VERSION ""

NS_ :

BS_:

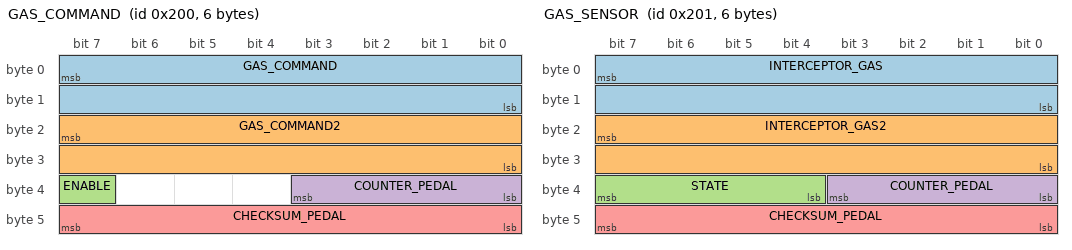
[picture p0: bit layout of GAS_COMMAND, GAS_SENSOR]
BO_ 512 GAS_COMMAND: 6 NEO
 SG_ GAS_COMMAND : 7|16@0+ (0.125677,-75.909) [0|1] "" INTERCEPTOR
 SG_ GAS_COMMAND2 : 23|16@0+ (0.251976,-76.601) [0|1] "" INTERCEPTOR
 SG_ ENABLE : 39|1@0+ (1,0) [0|1] "" INTERCEPTOR
 SG_ COUNTER_PEDAL : 35|4@0+ (1,0) [0|15] "" INTERCEPTOR
 SG_ CHECKSUM_PEDAL : 47|8@0+ (1,0) [0|255] "" INTERCEPTOR

BO_ 513 GAS_SENSOR: 6 INTERCEPTOR
 SG_ INTERCEPTOR_GAS : 7|16@0+ (0.125677,-75.909) [0|1] "" NEO
 SG_ INTERCEPTOR_GAS2 : 23|16@0+ (0.251976,-76.601) [0|1] "" NEO
 SG_ STATE : 39|4@0+ (1,0) [0|15] "" NEO
 SG_ COUNTER_PEDAL : 35|4@0+ (1,0) [0|15] "" NEO
 SG_ CHECKSUM_PEDAL : 47|8@0+ (1,0) [0|255] "" NEO

BO_ 189 EBCMRegenPaddle: 7 K17_EBCM
 SG_ RegenPaddle : 7|4@0+ (1,0) [0|0] ""  NEO

BO_ 190 ECMAcceleratorPos: 6 K20_ECM
 SG_ BrakePedalPos : 15|8@0+ (1,0) [0|0] "sticky"  NEO
 SG_ GasPedalAndAcc : 23|8@0+ (1,0) [0|0] ""  NEO

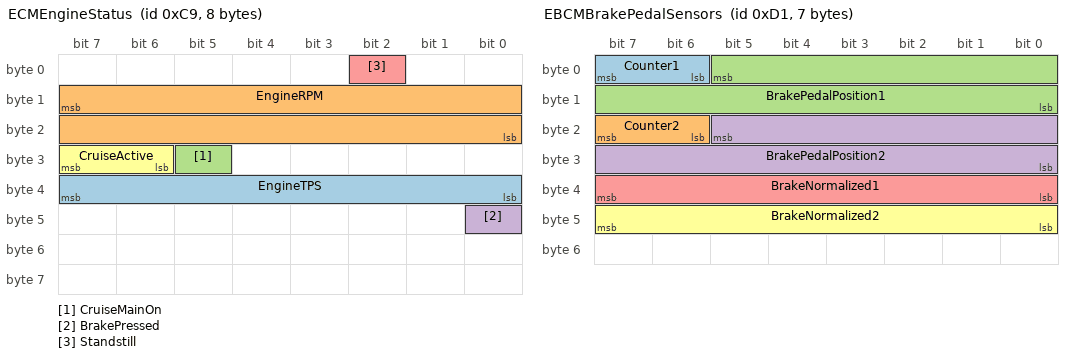
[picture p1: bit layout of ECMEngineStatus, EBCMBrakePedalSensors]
BO_ 201 ECMEngineStatus: 8 K20_ECM
 SG_ EngineTPS : 39|8@0+ (0.392156863,0) [0|100.000000065] "%" NEO
 SG_ EngineRPM : 15|16@0+ (0.25,0) [0|0] "RPM" NEO
 SG_ CruiseMainOn : 29|1@0+ (1,0) [0|1] "" NEO
 SG_ BrakePressed : 40|1@0+ (1,0) [0|1] "" NEO
 SG_ Standstill : 2|1@0+ (1,0) [0|1] "" NEO
 SG_ CruiseActive : 31|2@0+ (1,0) [0|3] "" NEO

BO_ 209 EBCMBrakePedalSensors: 7 K17_EBCM
 SG_ Counter1 : 7|2@0+ (1,0) [0|3] "" XXX
 SG_ Counter2 : 23|2@0+ (1,0) [0|3] "" XXX
 SG_ BrakePedalPosition1 : 5|14@0+ (1,0) [0|16383] "" XXX
 SG_ BrakePedalPosition2 : 21|14@0- (-1,0) [0|16383] "" XXX
 SG_ BrakeNormalized1 : 39|8@0+ (1,0) [0|255] "" XXX
 SG_ BrakeNormalized2 : 47|8@0- (-1,0) [0|255] "" XXX

BO_ 241 EBCMBrakePedalPosition: 6 K17_EBCM
 SG_ BrakePressed : 1|1@0+ (1,0) [0|1] "" XXX
 SG_ BrakePedalPosition : 15|8@0+ (1,0) [0|255] ""  NEO

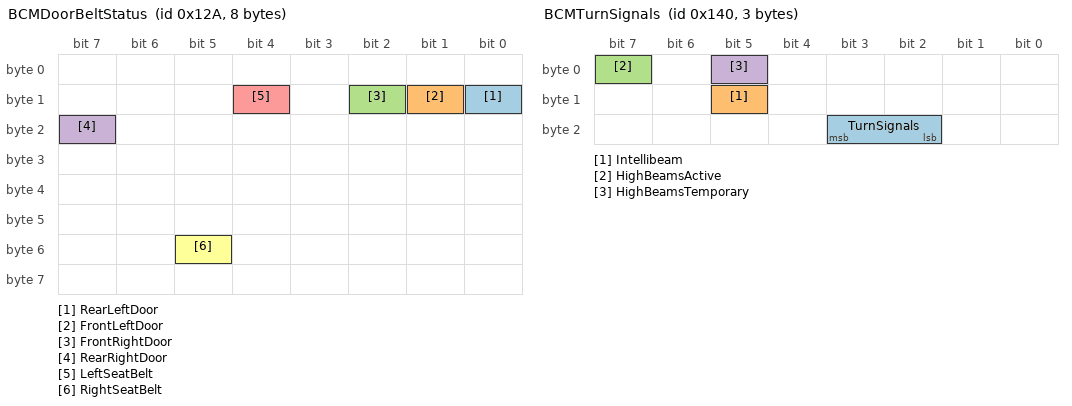
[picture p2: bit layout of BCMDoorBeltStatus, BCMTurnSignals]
BO_ 298 BCMDoorBeltStatus: 8 K9_BCM
 SG_ RearLeftDoor : 8|1@0+ (1,0) [0|0] ""  NEO
 SG_ FrontLeftDoor : 9|1@0+ (1,0) [0|0] ""  NEO
 SG_ FrontRightDoor : 10|1@0+ (1,0) [0|0] ""  NEO
 SG_ RearRightDoor : 23|1@0+ (1,0) [0|0] ""  NEO
 SG_ LeftSeatBelt : 12|1@0+ (1,0) [0|0] ""  NEO
 SG_ RightSeatBelt : 53|1@0+ (1,0) [0|0] ""  NEO

BO_ 309 ECMPRDNL: 8 K20_ECM
 SG_ PRNDL : 2|3@0+ (1,0) [0|0] ""  NEO
 SG_ ESPButton : 4|1@0+ (1,0) [0|1] "" XXX

BO_ 320 BCMTurnSignals: 3 K9_BCM
 SG_ TurnSignals : 19|2@0+ (1,0) [0|0] ""  NEO
 SG_ Intellibeam : 13|1@0+ (1,0) [0|1] "" XXX
 SG_ HighBeamsActive : 7|1@0+ (1,0) [0|1] "" XXX
 SG_ HighBeamsTemporary : 5|1@0+ (1,0) [0|1] "" XXX

BO_ 328 PSCM_148: 1 K43_PSCM

BO_ 381 ESPStatus: 6 K20_ECM
 SG_ TractionControlOn : 5|1@0+ (1,0) [0|0] ""  NEO
 SG_ MSG17D_AccPower : 35|12@0- (1,0) [0|0] ""  NEO

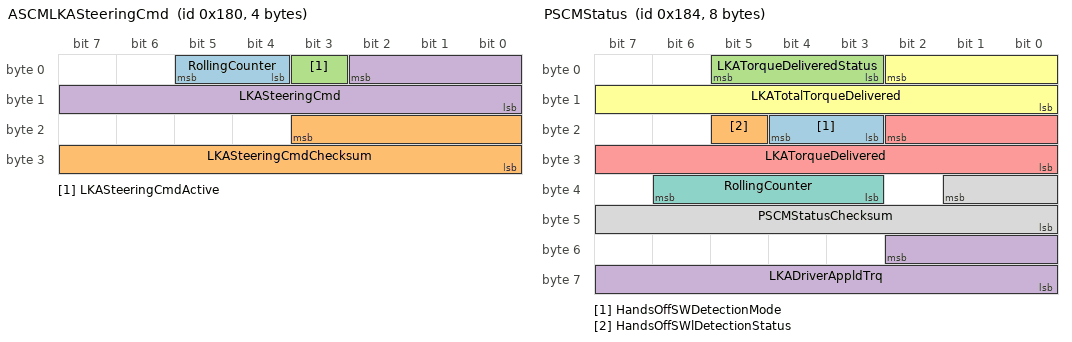
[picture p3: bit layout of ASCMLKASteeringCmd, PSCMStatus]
BO_ 384 ASCMLKASteeringCmd: 4 NEO
 SG_ RollingCounter : 5|2@0+ (1,0) [0|0] ""  NEO
 SG_ LKASteeringCmdChecksum : 19|12@0+ (1,0) [0|0] ""  NEO
 SG_ LKASteeringCmdActive : 3|1@0+ (1,0) [0|0] ""  NEO
 SG_ LKASteeringCmd : 2|11@0- (1,0) [0|0] ""  NEO

BO_ 388 PSCMStatus: 8 K43_PSCM
 SG_ HandsOffSWDetectionMode : 20|2@0+ (1,0) [0|3] "" NEO
 SG_ HandsOffSWlDetectionStatus : 21|1@0+ (1,0) [0|1] "" NEO
 SG_ LKATorqueDeliveredStatus : 5|3@0+ (1,0) [0|7] "" NEO
 SG_ LKADriverAppldTrq : 50|11@0- (0.01,0) [-10.24|10.23] "Nm" NEO
 SG_ LKATorqueDelivered : 18|11@0- (0.01,0) [0|1] "" NEO
 SG_ LKATotalTorqueDelivered : 2|11@0- (0.01,0) [-10.24|10.23] "Nm" NEO
 SG_ RollingCounter : 38|4@0+ (1,0) [0|15] "" XXX
 SG_ PSCMStatusChecksum : 33|10@0+ (1,0) [0|1023] "" XXX

BO_ 417 AcceleratorPedal: 7 XXX
 SG_ AcceleratorPedal : 55|8@0+ (1,0) [0|0] ""  NEO

BO_ 451 GasAndAcc: 8 XXX
 SG_ GasPedalAndAcc2 : 55|8@0+ (1,0) [0|0] ""  NEO

BO_ 452 AcceleratorPedal2: 8 XXX
 SG_ CruiseState : 15|3@0+ (1,0) [0|7] ""  NEO
 SG_ AcceleratorPedal2 : 47|8@0+ (1,0) [0|0] ""  NEO

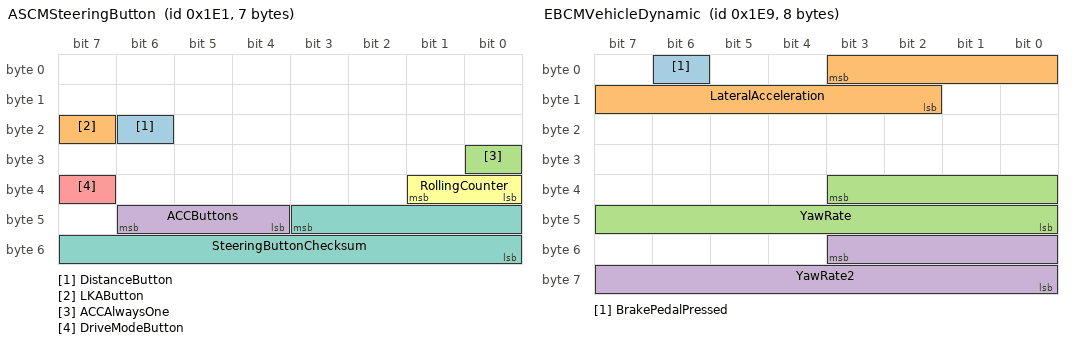
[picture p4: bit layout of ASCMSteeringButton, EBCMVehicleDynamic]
BO_ 481 ASCMSteeringButton: 7 K124_ASCM
 SG_ DistanceButton : 22|1@0+ (1,0) [0|0] ""  NEO
 SG_ LKAButton : 23|1@0+ (1,0) [0|0] ""  NEO
 SG_ ACCAlwaysOne : 24|1@0+ (1,0) [0|1] "" XXX
 SG_ ACCButtons : 46|3@0+ (1,0) [0|0] ""  NEO
 SG_ DriveModeButton : 39|1@0+ (1,0) [0|1] "" XXX
 SG_ RollingCounter : 33|2@0+ (1,0) [0|3] "" NEO
 SG_ SteeringButtonChecksum : 43|12@0+ (1,0) [0|255] "" NEO

BO_ 485 PSCMSteeringAngle: 8 K43_PSCM
 SG_ SteeringWheelAngle : 15|16@0- (0.0625,0) [-2047|2047] "deg"  NEO
 SG_ SteeringWheelRate : 27|12@0- (1,0) [-2047|2047] "deg/s"  NEO

BO_ 489 EBCMVehicleDynamic: 8 K17_EBCM
 SG_ BrakePedalPressed : 6|1@0+ (1,0) [0|0] "" NEO
 SG_ LateralAcceleration : 3|10@0- (0.161,0) [-2047|2047] "m/s2" NEO
 SG_ YawRate : 35|12@0- (0.625,0) [0|1] "" NEO
 SG_ YawRate2 : 51|12@0- (0.0625,0) [-2047|2047] "grad/s" NEO

BO_ 352 BCMImmobilizer: 5 K9_BCM
 SG_ ImmobilizerInfo : 7|32@0+ (1,0) [0|4294967295] "" XXX

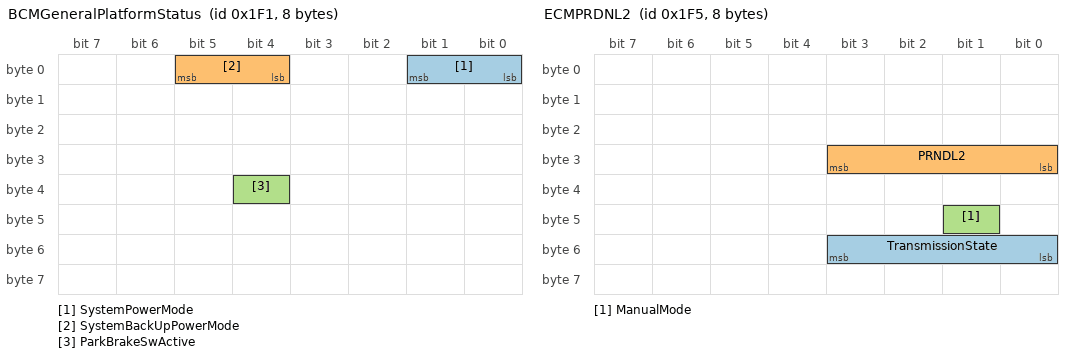
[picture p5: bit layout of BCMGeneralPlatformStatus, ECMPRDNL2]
BO_ 497 BCMGeneralPlatformStatus: 8 K9_BCM
 SG_ SystemPowerMode : 1|2@0+ (1,0) [0|3] "" XXX
 SG_ SystemBackUpPowerMode : 5|2@0+ (1,0) [0|3] "" XXX
 SG_ ParkBrakeSwActive : 36|1@0+ (1,0) [0|3] "" XXX

BO_ 501 ECMPRDNL2: 8 K20_ECM
 SG_ TransmissionState : 48|4@1+ (1,0) [0|7] "" NEO
 SG_ PRNDL2 : 27|4@0+ (1,0) [0|255] "" NEO
 SG_ ManualMode : 41|1@0+ (1,0) [0|1] "" NEO

BO_ 532 BRAKE_RELATED: 6 XXX
 SG_ UserBrakePressure : 0|9@0+ (1,0) [0|511] "" XXX

BO_ 560 EPBStatus: 8 EPB
 SG_ EPBClosed : 12|1@0+ (1,0) [0|1] ""  NEO

BO_ 562 EBCMFrictionBrakeStatus: 8 K17_EBCM
 SG_ FrictionBrakeUnavailable : 46|1@0+ (1,0) [0|1] "" XXX

BO_ 608 SPEED_RELATED: 8 XXX
 SG_ RollingCounter : 5|2@0+ (1,0) [0|0] "" XXX
 SG_ ClusterSpeed : 31|8@0+ (1,0) [0|0] "" XXX

BO_ 711 BECMBatteryVoltageCurrent: 6 K17_EBCM
 SG_ HVBatteryVoltage : 31|12@0+ (0.125,0) [0|511.875] "V"  NEO
 SG_ HVBatteryCurrent : 12|13@0- (0.15,0) [-614.4|614.25] "A"  NEO

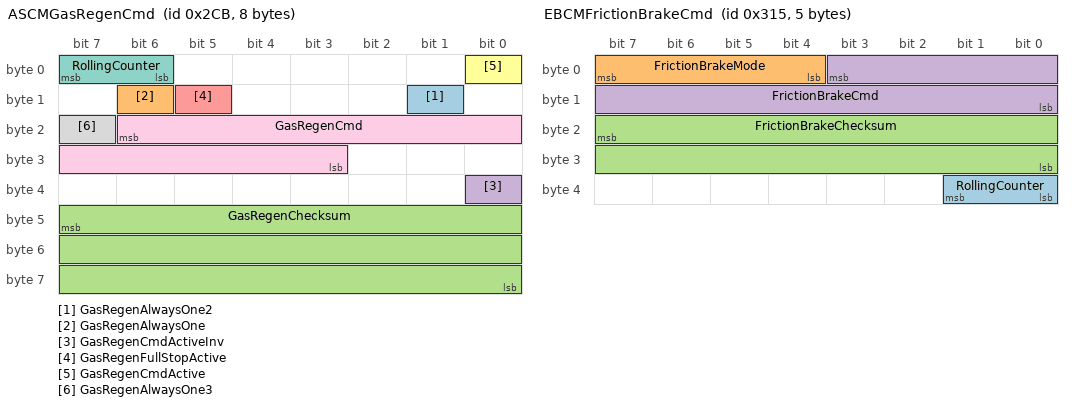
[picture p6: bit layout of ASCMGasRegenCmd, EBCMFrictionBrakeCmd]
BO_ 715 ASCMGasRegenCmd: 8 K124_ASCM
 SG_ GasRegenAlwaysOne2 : 9|1@0+ (1,0) [0|1] ""  NEO
 SG_ GasRegenAlwaysOne : 14|1@0+ (1,0) [0|1] ""  NEO
 SG_ GasRegenChecksum : 47|24@0+ (1,0) [0|0] ""  NEO
 SG_ GasRegenCmdActiveInv : 32|1@0+ (1,0) [0|0] ""  NEO
 SG_ GasRegenFullStopActive : 13|1@0+ (1,0) [0|0] ""  NEO
 SG_ GasRegenCmdActive : 0|1@0+ (1,0) [0|0] ""  NEO
 SG_ RollingCounter : 7|2@0+ (1,0) [0|0] ""  NEO
 SG_ GasRegenAlwaysOne3 : 23|1@0+ (1,0) [0|1] ""  NEO
 SG_ GasRegenCmd : 22|12@0+ (1,0) [0|0] ""  NEO

BO_ 717 ASCM_2CD: 5 K124_ASCM

BO_ 761 BRAKE_RELATED_2: 7 XXX
 SG_ UserBrakePressure2 : 47|9@0+ (1,0) [0|511] "" XXX

BO_ 789 EBCMFrictionBrakeCmd: 5 K124_ASCM
 SG_ RollingCounter : 33|2@0+ (1,0) [0|0] ""  NEO
 SG_ FrictionBrakeMode : 7|4@0+ (1,0) [0|0] ""  NEO
 SG_ FrictionBrakeChecksum : 23|16@0+ (1,0) [0|0] ""  NEO
 SG_ FrictionBrakeCmd : 3|12@0- (1,0) [0|0] ""  NEO

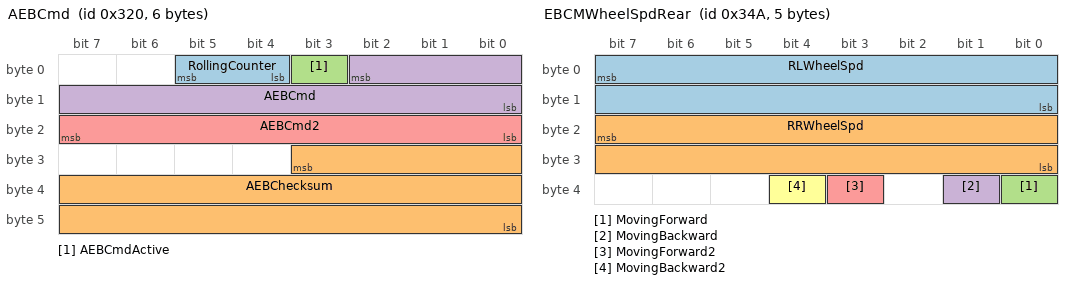
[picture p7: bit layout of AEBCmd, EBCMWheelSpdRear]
BO_ 800 AEBCmd: 6 K124_ASCM
 SG_ RollingCounter : 5|2@0+ (1,0) [0|3] "" NEO
 SG_ AEBChecksum : 27|20@0+ (1,0) [0|0] "" NEO
 SG_ AEBCmdActive : 3|1@1+ (1,0) [0|1] "" NEO
 SG_ AEBCmd : 2|11@0+ (1,0) [0|0] "" NEO
 SG_ AEBCmd2 : 23|8@0+ (1,0) [0|0] "" NEO

BO_ 810 TCICOnStarGPSPosition: 8 K73_TCIC
 SG_ GPSLongitude : 39|32@0+ (1,-2147483648) [0|0] "milliarcsecond"  NEO
 SG_ GPSLatitude : 7|32@0+ (1,0) [0|0] "milliarcsecond"  NEO

BO_ 840 EBCMWheelSpdFront: 5 K17_EBCM
 SG_ FLWheelSpd : 7|16@0+ (0.0311,0) [0|255] "km/h"  NEO
 SG_ FRWheelSpd : 23|16@0+ (0.0311,0) [0|255] "km/h"  NEO

BO_ 842 EBCMWheelSpdRear: 5 K17_EBCM
 SG_ RLWheelSpd : 7|16@0+ (0.0311,0) [0|255] "km/h"  NEO
 SG_ RRWheelSpd : 23|16@0+ (0.0311,0) [0|255] "km/h"  NEO
 SG_ MovingForward : 32|1@0+ (1,0) [0|1] "" XXX
 SG_ MovingBackward : 33|1@0+ (1,0) [0|1] "" XXX
 SG_ MovingForward2 : 35|1@1+ (1,0) [0|1] "" XXX
 SG_ MovingBackward2 : 36|1@0+ (1,0) [0|1] "" XXX

BO_ 869 ASCM_365: 4 K124_ASCM

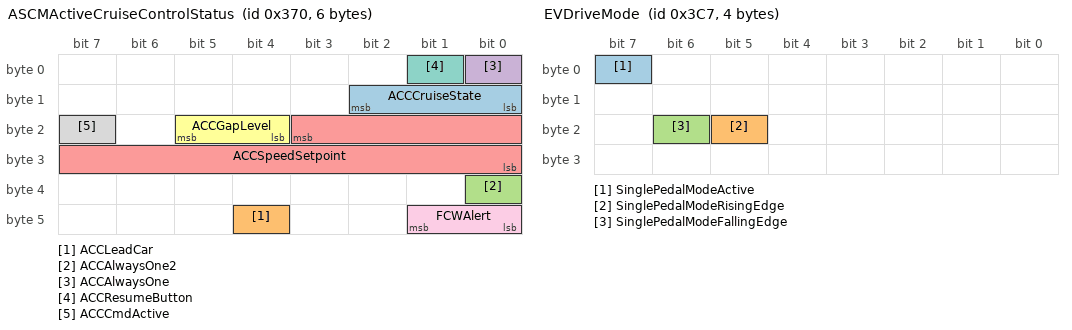
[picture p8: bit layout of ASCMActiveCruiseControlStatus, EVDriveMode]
BO_ 880 ASCMActiveCruiseControlStatus: 6 K124_ASCM
 SG_ ACCCruiseState : 8|3@1+ (1,0) [0|7] "" XXX
 SG_ ACCLeadCar : 44|1@0+ (1,0) [0|0] "" Vector__XXX
 SG_ ACCAlwaysOne2 : 32|1@0+ (1,0) [0|0] "" Vector__XXX
 SG_ ACCAlwaysOne : 0|1@0+ (1,0) [0|0] "" Vector__XXX
 SG_ ACCSpeedSetpoint : 19|12@0+ (0.0625,0) [0|255.9375] "km/h"  NEO
 SG_ ACCGapLevel : 21|2@0+ (1,0) [0|0] ""  NEO
 SG_ ACCResumeButton : 1|1@0+ (1,0) [0|0] ""  NEO
 SG_ ACCCmdActive : 23|1@0+ (1,0) [0|0] ""  NEO
 SG_ FCWAlert : 41|2@0+ (1,0) [0|3] "" XXX

BO_ 967 EVDriveMode: 4 XXX
 SG_ SinglePedalModeActive : 7|1@0+ (1,0) [0|1] "" XXX
 SG_ SinglePedalModeRisingEdge : 21|1@0+ (1,0) [0|1] "" XXX
 SG_ SinglePedalModeFallingEdge : 22|1@0+ (1,0) [0|1] "" XXX

BO_ 977 ECMCruiseControl: 8 K20_ECM
 SG_ CruiseActive : 39|1@0+ (1,0) [0|3] "" NEO
 SG_ CruiseSetSpeed : 19|12@0+ (0.0625,0) [0|0] "km/h" NEO

BO_ 1001 ECMVehicleSpeed: 8 K20_ECM
 SG_ VehicleSpeed : 7|16@0+ (0.01,0) [0|0] "mph"  NEO
 SG_ VehicleSpeedLeft : 39|16@0+ (0.01,0) [0|0] "mph" NEO

BO_ 1033 ASCMKeepAlive: 7 NEO
 SG_ ASCMKeepAliveAllZero : 7|56@0+ (1,0) [0|0] ""  NEO

BO_ 1034 ASCM_40A: 7 K124_ASCM

BO_ 1217 ECMEngineCoolantTemp: 8 K20_ECM
 SG_ EngineCoolantTemp : 23|8@0+ (1,-40) [0|0] "C"  NEO

BO_ 1249 VIN_Part2: 8 K20_ECM
 SG_ VINPart2 : 7|64@0+ (1,0) [0|0] ""  NEO

BO_ 1296 ASCM_510: 4 K124_ASCM

BO_ 1300 VIN_Part1: 8 K20_ECM
 SG_ VINPart1 : 7|64@0+ (1,0) [0|0] ""  NEO

BO_ 1912 PSCM_778: 8 K43_PSCM

BO_ 1930 ASCM_78A: 7 K124_ASCM

BO_TX_BU_ 384 : K124_ASCM,NEO;
BO_TX_BU_ 880 : NEO,K124_ASCM;
BO_TX_BU_ 1033 : K124_ASCM,NEO;
BO_TX_BU_ 715 : NEO,K124_ASCM;
BO_TX_BU_ 789 : NEO,K124_ASCM;
BO_TX_BU_ 800 : NEO,K124_ASCM;

BU_: AWD ECU TCU ESP SAS ABS

CM_ SG_ 357 GEAR "13P, 26R, 13N, 24D";
CM_ SG_ 605 PED_BRAKE "3: no brake, 4: brake";
CM_ SG_ 605 BRAKE_WARNING "Flashing brake warning and audible alert for potential forward collision";
CM_ SG_ 579 STEERING_ANGLE "steering angle aligns with 0.022 factor and -45.06 offset";
CM_ SG_ 863 SPEED_SIGN "speed limit in MPH";
CM_ SG_ 863 SPEED_SIGN_CAM "1: The speed limit is recognized by the camera. 0: speed limit is map based or is not available";
CM_ SG_ 863 STOP_SIGN "value 9 when stop sign is active";
CM_ SG_ 1157 SBS_WARNING_DISTANCE "1 far, 2 mid, 3 near";
CM_ SG_ 1157 SBS_SCBC "1 off, 2 on";
CM_ SG_ 1157 LKAS_ASSIT_TIMING "1 at, 0 before";
CM_ SG_ 1157 LKAS_SENSETIVITY "0 low, 1 high";
CM_ SG_ 1157 LANEE_DEPARTURE_ALERT "1 off, 2 on";
CM_ SG_ 1157 WARNING "1 Rare, 0 often";
CM_ SG_ 1088 LANE_LINES "0 LKAS disabled, 1 no lines, 2 two lines, 3 left line, 4 right line";
CM_ SG_ 1088 TJA "2: crz not active,  3: TJA not allowed,  4: TJA allowed";
CM_ SG_ 1088 TJA_TRANSITION "3: if TJA signal is 3, otherwise set to 0";
CM_ SG_ 1045 ABS_MALFUNCTION "off: 0, solid: 1, slow blink: 2, fast blink: 3";
CM_ SG_ 120 VEHICLE_ACC_X "Vehicle acceleration of X-axis wrt. NED frame.";
CM_ SG_ 120 VEHICLE_ACC_Y "Vehicle acceleration of Y-axis wrt. NED frame.";
CM_ SG_ 157 CAN_OFF "Disengage Cruise if enabled, if already disabled  TURN it OFF ";
CM_ SG_ 552 GEAR "0 Shifting, 1 P, 2 R, 3 N, 4 D";
CM_ SG_ 552 GEAR_BOX "0 P, 14 R, 1 though 6 D for speeds, 15 Shift";
CM_ SG_ 540 HANDS_ON_STEER_WARN "0 no warning, b warning";
CM_ SG_ 540 DISTANCE_SETTING "Radar distance 0: disabled, 1: 4 bars, 2: 3 bars, 3: 2 bars, 4: 1 bar";
CM_ SG_ 1143 REAR_CT_ALERT "Rear Cross Traffic Alert";
VAL_ 3 StW_Angl 16383 "SNA" ;
VAL_ 3 StW_AnglSens_Id 2 "MUST" 0 "PSBL" 1 "SELF" ;
VAL_ 3 StW_AnglSens_Stat 2 "ERR" 3 "ERR_INI" 1 "INI" 0 "OK" ;
VAL_ 3 StW_AnglSpd 16383 "SNA" ;
VAL_ 14 StW_AnglHP 16383 "SNA" ;
VAL_ 14 StW_AnglHP_Spd 16383 "SNA" ;
VAL_ 14 StW_AnglHP_Sens_Stat 3 "SNA" 2 "ERR" 1 "INI" 0 "OK" ;
VAL_ 14 StW_AnglHP_Sens_Id 3 "SNA" 2 "KOSTAL" 1 "DELPHI" 0 "TEST" ;
VAL_ 69 SpdCtrlLvr_Stat 32 "DN_1ST" 16 "UP_1ST" 8 "DN_2ND" 4 "UP_2ND" 2 "RWD" 1 "FWD" 0 "IDLE" ;
VAL_ 69 DTR_Dist_Rq 255 "SNA" 200 "ACC_DIST_7" 166 "ACC_DIST_6" 133 "ACC_DIST_5" 100 "ACC_DIST_4" 66 "ACC_DIST_3" 33 "ACC_DIST_2" 0 "ACC_DIST_1" ;
VAL_ 69 TurnIndLvr_Stat 3 "SNA" 2 "RIGHT" 1 "LEFT" 0 "IDLE" ;
VAL_ 69 HiBmLvr_Stat 3 "SNA" 2 "HIBM_FLSH_ON_PSD" 1 "HIBM_ON_PSD" 0 "IDLE" ;
VAL_ 69 WprWashSw_Psd 3 "SNA" 2 "WASH" 1 "TIPWIPE" 0 "NPSD" ;
VAL_ 69 WprWash_R_Sw_Posn_V2 3 "SNA" 2 "WASH" 1 "INTERVAL" 0 "OFF" ;
VAL_ 69 StW_Lvr_Stat 4 "STW_BACK" 3 "STW_FWD" 2 "STW_DOWN" 1 "STW_UP" 0 "NPSD" ;
VAL_ 69 StW_Cond_Psd 3 "SNA" 2 "DOWN" 1 "UP" 0 "NPSD" ;
VAL_ 69 HrnSw_Psd 3 "SNA" 2 "NDEF2" 1 "PSD" 0 "NPSD" ;
VAL_ 69 StW_Sw00_Psd 1 "PRESSED" 0 "NOT_PRESSED_SNA" ;
VAL_ 69 StW_Sw01_Psd 1 "PRESSED" 0 "NOT_PRESSED_SNA" ;
VAL_ 69 StW_Sw03_Psd 1 "PRESSED" 0 "NOT_PRESSED_SNA" ;
VAL_ 69 StW_Sw04_Psd 1 "PRESSED" 0 "NOT_PRESSED_SNA" ;
VAL_ 69 WprSw6Posn 7 "SNA" 6 "STAGE2" 5 "STAGE1" 4 "INTERVAL4" 3 "INTERVAL3" 2 "INTERVAL2" 1 "INTERVAL1" 0 "OFF" ;
VAL_ 257 GTW_epasControlType 0 "WITHOUT" 1 "WITH_ANGLE" 3 "WITH_BOTH" 2 "WITH_TORQUE" ;
VAL_ 109 StW_Sw_Stat3 7 "SNA" 6 "NDEF6" 5 "NDEF5" 4 "NDEF4" 3 "PLUS_MINUS" 2 "MINUS" 1 "PLUS" 0 "NPSD" ;
VAL_ 109 MsgTxmtId 3 "NDEF3" 2 "NDEF2" 1 "SCCM" 0 "EWM" ;
VAL_ 109 TSL_RND_Posn_StW 15 "SNA" 8 "D" 6 "INI" 4 "N_DOWN" 2 "N_UP" 1 "R" 0 "IDLE" ;
VAL_ 109 TSL_P_Psd_StW 3 "SNA" 2 "INI" 1 "PSD" 0 "IDLE" ;
VAL_ 257 GTW_epasEmergencyOn 1 "EMERGENCY_POWER" 0 "NONE" ;
VAL_ 257 GTW_epasLDWEnabled 1 "ALLOWED" 0 "INHIBITED" ;
VAL_ 257 GTW_epasPowerMode 0 "DRIVE_OFF" 1 "DRIVE_ON" 3 "LOAD_SHED" 2 "SHUTTING_DOWN" 15 "SNA" ;
VAL_ 257 GTW_epasTuneRequest 1 "DM_COMFORT" 3 "DM_SPORT" 2 "DM_STANDARD" 0 "FAIL_SAFE_DEFAULT" 4 "RWD_COMFORT" 6 "RWD_SPORT" 5 "RWD_STANDARD" 7 "SNA" ;
VAL_ 264 DI_torqueDriver -4096 "SNA" ;
VAL_ 264 DI_torqueMotor -4096 "SNA" ;
VAL_ 264 DI_soptState 7 "SOPT_TEST_SNA" 4 "SOPT_TEST_NOT_RUN" 3 "SOPT_TEST_PASSED" 2 "SOPT_TEST_FAILED" 1 "SOPT_TEST_IN_PROGRESS" 0 "SOPT_PRE_TEST" ;
VAL_ 264 DI_motorRPM -32768 "SNA" ;
VAL_ 264 DI_pedalPos 255 "SNA" ;
VAL_ 280 DI_torqueEstimate -2048 "SNA" ;
VAL_ 280 DI_gear 7 "DI_GEAR_SNA" 4 "DI_GEAR_D" 3 "DI_GEAR_N" 2 "DI_GEAR_R" 1 "DI_GEAR_P" 0 "DI_GEAR_INVALID" ;
VAL_ 280 DI_brakePedal 1 "Applied" 0 "Not_applied" ;
VAL_ 280 DI_vehicleSpeed 4095 "SNA" ;
VAL_ 280 DI_gearRequest 7 "DI_GEAR_SNA" 4 "DI_GEAR_D" 3 "DI_GEAR_N" 2 "DI_GEAR_R" 1 "DI_GEAR_P" 0 "DI_GEAR_INVALID" ;
VAL_ 280 DI_torqueInterfaceFailure 1 "TORQUE_INTERFACE_FAILED" 0 "TORQUE_INTERFACE_NORMAL" ;
VAL_ 280 DI_brakePedalState 3 "SNA" 2 "INVALID" 1 "ON" 0 "OFF" ;
VAL_ 280 DI_epbParkRequest 1 "Park_requested" 0 "No_request" ;
VAL_ 280 DI_epbInterfaceReady 1 "EPB_INTERFACE_READY" 0 "EPB_INTERFACE_NOT_READY" ;
VAL_ 309 ESP_absBrakeEvent 1 "ACTIVE" 0 "NOT_ACTIVE" ;
VAL_ 309 ESP_brakeDiscWipingActive 1 "ACTIVE" 0 "INACTIVE" ;
VAL_ 309 ESP_brakeLamp 0 "OFF" 1 "ON" ;
VAL_ 309 ESP_espFaultLamp 0 "OFF" 1 "ON" ;
VAL_ 309 ESP_espLampFlash 1 "FLASH" 0 "OFF" ;
VAL_ 309 ESP_hillStartAssistActive 1 "ACTIVE" 0 "INACTIVE" 2 "NOT_AVAILABLE" 3 "SNA" ;
VAL_ 309 ESP_absFaultLamp 0 "OFF" 1 "ON" ;
VAL_ 309 ESP_espOffLamp 0 "OFF" 1 "ON" ;
VAL_ 309 ESP_stabilityControlSts 2 "ENGAGED" 3 "FAULTED" 5 "INIT" 4 "NOT_CONFIGURED" 0 "OFF" 1 "ON" ;
VAL_ 309 ESP_tcLampFlash 1 "FLASH" 0 "OFF" ;
VAL_ 568 UI_mapSpeedLimit 31 "SNA" 30 "UNLIMITED" 29 "LESS_OR_EQ_160" 28 "LESS_OR_EQ_150" 27 "LESS_OR_EQ_140" 26 "LESS_OR_EQ_130" 25 "LESS_OR_EQ_120" 24 "LESS_OR_EQ_115" 23 "LESS_OR_EQ_110" 22 "LESS_OR_EQ_105" 21 "LESS_OR_EQ_100" 20 "LESS_OR_EQ_95" 19 "LESS_OR_EQ_90" 18 "LESS_OR_EQ_85" 17 "LESS_OR_EQ_80" 16 "LESS_OR_EQ_75" 15 "LESS_OR_EQ_70" 14 "LESS_OR_EQ_65" 13 "LESS_OR_EQ_60" 12 "LESS_OR_EQ_55" 11 "LESS_OR_EQ_50" 10 "LESS_OR_EQ_45" 9 "LESS_OR_EQ_40" 8 "LESS_OR_EQ_35" 7 "LESS_OR_EQ_30" 6 "LESS_OR_EQ_25" 5 "LESS_OR_EQ_20" 4 "LESS_OR_EQ_15" 3 "LESS_OR_EQ_10" 2 "LESS_OR_EQ_7" 1 "LESS_OR_EQ_5" 0 "UNKNOWN" ;
VAL_ 569 DAS_leftLineUsage 3 "BLACKLISTED" 2 "FUSED" 1 "AVAILABLE" 0 "REJECTED_UNAVAILABLE" ;
VAL_ 569 DAS_rightLineUsage 3 "BLACKLISTED" 2 "FUSED" 1 "AVAILABLE" 0 "REJECTED_UNAVAILABLE" ;
VAL_ 569 DAS_leftFork 3 "LEFT_FORK_UNAVAILABLE" 2 "LEFT_FORK_SELECTED" 1 "LEFT_FORK_AVAILABLE" 0 "LEFT_FORK_NONE" ;
VAL_ 569 DAS_rightFork 3 "RIGHT_FORK_UNAVAILABLE" 2 "RIGHT_FORK_SELECTED" 1 "RIGHT_FORK_AVAILABLE" 0 "RIGHT_FORK_NONE" ;
VAL_ 521 DAS_locMode 3 "DAS_LOC_DRIVERLESS" 2 "DAS_LOC_RESTRICTED" 1 "DAS_LOC_NORMAL" 0 "DAS_LOC_OFF" ;
VAL_ 521 DAS_locState 7 "DAS_LOC_FAULT_SNA" 6 "DAS_LOC_AEB_ACTIVE" 2 "DAS_LOC_CANCEL_SILENT" 1 "DAS_LOC_CANCEL_GENERIC" 0 "DAS_LOC_HEALTHY" ;
VAL_ 521 DAS_locRequest 4 "DAS_RQ_PARK" 3 "DAS_RQ_HOLD" 2 "DAS_RQ_BACKWARD" 1 "DAS_RQ_FORWARD" 0 "DAS_RQ_IDLE" ;
VAL_ 521 DAS_locJerkMin 255 "SNA" ;
VAL_ 521 DAS_locJerkMax 255 "SNA" ;
VAL_ 521 DAS_locSpeed 2047 "SNA" ;
VAL_ 521 DAS_locAccelMin 511 "SNA" ;
VAL_ 521 DAS_locAccelMax 511 "SNA" ;
VAL_ 522 driverBrakeStatus 2 "APPLIED" 1 "NOT_APPLIED" ;
VAL_ 760 UI_mapSpeedLimitUnits 1 "KPH" 0 "MPH" ;
VAL_ 760 UI_userSpeedOffsetUnits 1 "KPH" 0 "MPH" ;
VAL_ 643 AirTemp_Insd 255 "SNA" ;
VAL_ 643 AirTemp_Outsd 254 "INIT" 255 "SNA" ;
VAL_ 643 Bckl_Sw_RL_Stat_SAM_R 2 "FLT" 1 "NOT" 0 "OK" 3 "SNA" ;
VAL_ 643 Bckl_Sw_RM_Stat_SAM_R 2 "FLT" 1 "NOT" 0 "OK" 3 "SNA" ;
VAL_ 643 Bckl_Sw_RR_Stat_SAM_R 2 "FLT" 1 "NOT" 0 "OK" 3 "SNA" ;
VAL_ 643 DL_RLtch_Stat 1 "CLS" 0 "NDEF0" 2 "OPN" 3 "SNA" ;
VAL_ 643 DrRLtch_FL_Stat 1 "CLS" 0 "NDEF0" 2 "OPN" 3 "SNA" ;
VAL_ 643 DrRLtch_FR_Stat 1 "CLS" 0 "NDEF0" 2 "OPN" 3 "SNA" ;
VAL_ 643 DrRLtch_RL_Stat 1 "CLS" 0 "NDEF0" 2 "OPN" 3 "SNA" ;
VAL_ 643 DrRLtch_RR_Stat 1 "CLS" 0 "NDEF0" 2 "OPN" 3 "SNA" ;
VAL_ 643 EngHd_Stat 1 "CLS" 0 "NDEF0" 2 "OPN" 3 "SNA" ;
VAL_ 643 LgtSens_Night 0 "DAY" 1 "NIGHT" ;
VAL_ 643 MPkBrk_Stat 1 "ENGG" 0 "RELS" ;
VAL_ 643 RevGr_Engg 0 "DISENGG" 1 "ENGG" 2 "NDEF2" 3 "SNA" ;
VAL_ 643 StW_Cond_Stat 3 "BLINK" 1 "NDEF1" 0 "OFF" 2 "ON" ;
VAL_ 643 Trlr_Stat 2 "NDEF2" 0 "NONE" 1 "OK" 3 "SNA" ;
VAL_ 697 DAS_setSpeed 4095 "SNA" ;
VAL_ 697 DAS_accState 15 "FAULT_SNA" 13 "ACC_CANCEL_GENERIC_SILENT" 11 "APC_SELFPARK_START" 10 "APC_UNPARK_COMPLETE" 9 "APC_PAUSE" 8 "APC_ABORT" 7 "APC_COMPLETE" 6 "APC_FORWARD" 5 "APC_BACKWARD" 4 "ACC_ON" 3 "ACC_HOLD" 0 "ACC_CANCEL_GENERIC" ;
VAL_ 697 DAS_aebEvent 3 "AEB_SNA" 2 "AEB_FAULT" 1 "AEB_ACTIVE" 0 "AEB_NOT_ACTIVE" ;
VAL_ 697 DAS_jerkMin 511 "SNA" ;
VAL_ 697 DAS_jerkMax 255 "SNA" ;
VAL_ 697 DAS_accelMin 511 "SNA" ;
VAL_ 697 DAS_accelMax 511 "SNA" ;
VAL_ 792 BOOT_STATE 2 "Init" 3 "SNA" 0 "closed" 1 "open" ;
VAL_ 792 CERRD 1 "CAN error detect" 0 "no Can error detected" ;
VAL_ 792 DAY 1 "Init" 0 "SNA" ;
VAL_ 792 DOOR_STATE_FL 2 "Init" 3 "SNA" 0 "closed" 1 "open" ;
VAL_ 792 DOOR_STATE_FR 2 "Init" 3 "SNA" 0 "closed" 1 "open" ;
VAL_ 792 DOOR_STATE_FrontTrunk 2 "Init" 3 "SNA" 0 "closed" 1 "open" ;
VAL_ 792 DOOR_STATE_RL 2 "Init" 3 "SNA" 0 "closed" 1 "open" ;
VAL_ 792 DOOR_STATE_RR 2 "Init" 3 "SNA" 0 "closed" 1 "open" ;
VAL_ 792 GTW_updateInProgress 1 "IN_PROGRESS" 2 "IN_PROGRESS_NOT_USED" 3 "IN_PROGRESS_SNA" 0 "NOT_IN_PROGRESS" ;
VAL_ 792 Hour 30 "Init" 31 "SNA" ;
VAL_ 792 MCU_factoryMode 1 "FACTORY_MODE" 0 "NORMAL_MODE" ;
VAL_ 792 MCU_transportModeOn 0 "NORMAL_MODE" ;
VAL_ 792 MINUTE 62 "Init" 63 "SNA" ;
VAL_ 792 MONTH 1 "Init" 15 "SNA" ;
VAL_ 792 SECOND 62 "Init" 63 "SNA" ;
VAL_ 792 YEAR 126 "Init" 127 "SNA" ;
VAL_ 872 DI_aebState 2 "ENABLED" 4 "FAULT" 7 "SNA" 1 "STANDBY" 3 "STANDSTILL" 0 "UNAVAILABLE" ;
VAL_ 872 DI_analogSpeed 4095 "SNA" ;
VAL_ 872 DI_cruiseState 2 "ENABLED" 5 "FAULT" 0 "OFF" 4 "OVERRIDE" 7 "PRE_CANCEL" 6 "PRE_FAULT" 1 "STANDBY" 3 "STANDSTILL" ;
VAL_ 872 DI_digitalSpeed 255 "SNA" ;
VAL_ 872 DI_immobilizerState 2 "AUTHENTICATING" 3 "DISARMED" 6 "FAULT" 4 "IDLE" 0 "INIT_SNA" 1 "REQUEST" 5 "RESET" ;
VAL_ 872 DI_speedUnits 1 "KPH" 0 "MPH" ;
VAL_ 872 DI_state 3 "ABORT" 4 "ENABLE" 2 "FAULT" 1 "STANDBY" 0 "UNAVAILABLE" ;
VAL_ 872 DI_systemState 3 "ABORT" 4 "ENABLE" 2 "FAULT" 1 "STANDBY" 0 "UNAVAILABLE" ;
VAL_ 872 DI_vehicleHoldState 2 "BLEND_IN" 4 "BLEND_OUT" 6 "FAULT" 7 "INIT" 5 "PARK" 1 "STANDBY" 3 "STANDSTILL" 0 "UNAVAILABLE" ;
VAL_ 880 EPAS_currentTuneMode 1 "DM_COMFORT" 3 "DM_SPORT" 2 "DM_STANDARD" 0 "FAIL_SAFE_DEFAULT" 4 "RWD_COMFORT" 6 "RWD_SPORT" 5 "RWD_STANDARD" 7 "UNAVAILABLE" ;
VAL_ 880 EPAS_eacErrorCode 14 "EAC_ERROR_EPB_INHIBIT" 3 "EAC_ERROR_HANDS_ON" 7 "EAC_ERROR_HIGH_ANGLE_RATE_REQ" 9 "EAC_ERROR_HIGH_ANGLE_RATE_SAFETY" 6 "EAC_ERROR_HIGH_ANGLE_REQ" 8 "EAC_ERROR_HIGH_ANGLE_SAFETY" 10 "EAC_ERROR_HIGH_MMOT_SAFETY" 11 "EAC_ERROR_HIGH_TORSION_SAFETY" 0 "EAC_ERROR_IDLE" 12 "EAC_ERROR_LOW_ASSIST" 2 "EAC_ERROR_MAX_SPEED" 1 "EAC_ERROR_MIN_SPEED" 13 "EAC_ERROR_PINION_VEL_DIFF" 4 "EAC_ERROR_TMP_FAULT" 5 "EAR_ERROR_MAX_STEER_DELTA" 15 "SNA" ;
VAL_ 880 EPAS_eacStatus 2 "EAC_ACTIVE" 1 "EAC_AVAILABLE" 3 "EAC_FAULT" 0 "EAC_INHIBITED" 4 "SNA" ;
VAL_ 880 EPAS_handsOnLevel 0 "0" 1 "1" 2 "2" 3 "3" ;
VAL_ 880 EPAS_steeringFault 1 "FAULT" 0 "NO_FAULT" ;
VAL_ 880 EPAS_steeringRackForce 1022 "NOT_IN_SPEC" 1023 "SNA" ;
VAL_ 880 EPAS_steeringReduced 0 "NORMAL_ASSIST" 1 "REDUCED_ASSIST" ;
VAL_ 880 EPAS_torsionBarTorque 0 "SEE_SPECIFICATION" 4095 "SNA" 4094 "UNDEFINABLE_DATA" ;
VAL_ 904 MCU_clusterReadyForDrive 0 "NO_SNA" 1 "YES" ;
VAL_ 905 DAS_accSpeedLimit 1023 "SNA" 0 "NONE" ;
VAL_ 905 DAS_pmmObstacleSeverity 7 "PMM_SNA" 6 "PMM_ACCEL_LIMIT" 5 "PMM_CRASH_FRONT" 4 "PMM_CRASH_REAR" 3 "PMM_BRAKE_REQUEST" 2 "PMM_IMMINENT_FRONT" 1 "PMM_IMMINENT_REAR" 0 "PMM_NONE" ;
VAL_ 905 DAS_pmmLoggingRequest 1 "TRUE" 0 "FALSE" ;
VAL_ 905 DAS_activationFailureStatus 2 "LC_ACTIVATION_FAILED_2" 1 "LC_ACTIVATION_FAILED_1" 0 "LC_ACTIVATION_IDLE" ;
VAL_ 905 DAS_pmmUltrasonicsFaultReason 4 "PMM_ULTRASONICS_INVALID_MIA" 3 "PMM_ULTRASONICS_BLOCKED_BOTH" 2 "PMM_ULTRASONICS_BLOCKED_REAR" 1 "PMM_ULTRASONICS_BLOCKED_FRONT" 0 "PMM_ULTRASONICS_NO_FAULT" ;
VAL_ 905 DAS_pmmRadarFaultReason 2 "PMM_RADAR_INVALID_MIA" 1 "PMM_RADAR_BLOCKED_FRONT" 0 "PMM_RADAR_NO_FAULT" ;
VAL_ 905 DAS_pmmSysFaultReason 7 "PMM_FAULT_BRAKE_PEDAL_INHIBIT" 6 "PMM_FAULT_ROAD_TYPE" 5 "PMM_FAULT_DISABLED_BY_USER" 4 "PMM_FAULT_STEERING_ANGLE_RATE" 3 "PMM_FAULT_DI_FAULT" 2 "PMM_FAULT_SPEED" 1 "PMM_FAULT_DAS_DISABLED" 0 "PMM_FAULT_NONE" ;
VAL_ 905 DAS_pmmCameraFaultReason 2 "PMM_CAMERA_INVALID_MIA" 1 "PMM_CAMERA_BLOCKED_FRONT" 0 "PMM_CAMERA_NO_FAULT" ;
VAL_ 905 DAS_ACC_report 24 "ACC_REPORT_BEHAVIOR_REPORT" 23 "ACC_REPORT_CAMERA_ONLY" 22 "ACC_REPORT_RADAR_OBJ_FIVE" 21 "ACC_REPORT_CIPV_CUTTING_OUT" 20 "ACC_REPORT_MCVLR_IN_PATH" 19 "ACC_REPORT_MCVLR_DPP" 18 "ACC_REPORT_FLEET_SPEEDS" 17 "ACC_REPORT_TARGET_MCP" 16 "ACC_REPORT_RADAR_OBJ_TWO" 15 "ACC_REPORT_RADAR_OBJ_ONE" 14 "ACC_REPORT_LC_EXTERNAL_STATE_ACTIVE_RESTRICTED" 13 "ACC_REPORT_LC_EXTERNAL_STATE_ABORTED" 12 "ACC_REPORT_LC_EXTERNAL_STATE_ABORTING" 11 "ACC_REPORT_LC_HANDS_ON_REQD_STRUCK_OUT" 10 "ACC_REPORT_CSA" 9 "ACC_REPORT_TARGET_TYPE_FAULT" 8 "ACC_REPORT_TARGET_TYPE_IPSO" 7 "ACC_REPORT_TARGET_TYPE_TRAFFIC_LIGHT" 6 "ACC_REPORT_TARGET_TYPE_STOP_SIGN" 5 "ACC_REPORT_TARGET_CUTIN" 4 "ACC_REPORT_TARGET_MCVR" 3 "ACC_REPORT_TARGET_MCVL" 2 "ACC_REPORT_TARGET_IN_FRONT_OF_CIPV" 1 "ACC_REPORT_TARGET_CIPV" 0 "ACC_REPORT_TARGET_NONE" ;
VAL_ 905 DAS_lssState 7 "LSS_STATE_OFF" 6 "LSS_STATE_ABORT" 5 "LSS_STATE_BLINDSPOT" 4 "LSS_STATE_MONITOR" 3 "LSS_STATE_ELK" 2 "LSS_STATE_LKA" 1 "LSS_STATE_LDW" 0 "LSS_STATE_FAULT" ;
VAL_ 905 DAS_radarTelemetry 2 "RADAR_TELEMETRY_URGENT" 1 "RADAR_TELEMETRY_NORMAL" 0 "RADAR_TELEMETRY_IDLE" ;
VAL_ 905 DAS_robState 3 "ROB_STATE_MAPLESS" 2 "ROB_STATE_ACTIVE" 1 "ROB_STATE_MEASURE" 0 "ROB_STATE_INHIBITED" ;
VAL_ 905 DAS_driverInteractionLevel 2 "CONTINUED_DRIVER_NOT_INTERACTING" 1 "DRIVER_NOT_INTERACTING" 0 "DRIVER_INTERACTING" ;
VAL_ 905 DAS_ppOffsetDesiredRamp 128 "PP_NO_OFFSET" ;
VAL_ 905 DAS_longCollisionWarning 15 "FCM_LONG_COLLISION_WARNING_SNA" 12 "FCM_LONG_COLLISION_WARNING_VEHICLE_CIPV2" 11 "FCM_LONG_COLLISION_WARNING_VEHICLE_MCVR2" 10 "FCM_LONG_COLLISION_WARNING_VEHICLE_MCVR" 9 "FCM_LONG_COLLISION_WARNING_VEHICLE_MCVL2" 8 "FCM_LONG_COLLISION_WARNING_VEHICLE_MCVL" 7 "FCM_LONG_COLLISION_WARNING_VEHICLE_CUTIN" 6 "FCM_LONG_COLLISION_WARNING_VEHICLE_CIPV" 5 "FCM_LONG_COLLISION_WARNING_TFL_STOPLINE" 4 "FCM_LONG_COLLISION_WARNING_STOPSIGN_STOPLINE" 3 "FCM_LONG_COLLISION_WARNING_IPSO" 2 "FCM_LONG_COLLISION_WARNING_PEDESTRIAN" 1 "FCM_LONG_COLLISION_WARNING_VEHICLE_UNKNOWN" 0 "FCM_LONG_COLLISION_WARNING_NONE" ;
VAL_ 921 autopilotStatus 5 "ACTIVE_NAVIGATE_ON_AUTOPILOT" 4 "ACTIVE_2" 3 "ACTIVE_1" 2 "AVAILABLE" 1 "UNAVAILABLE" 0 "DISABLED" ;
VAL_ 921 DAS_blindSpotRearLeft 3 "SNA" 2 "WARNING_LEVEL_2" 1 "WARNING_LEVEL_1" 0 "NO_WARNING" ;
VAL_ 921 DAS_blindSpotRearRight 3 "SNA" 2 "WARNING_LEVEL_2" 1 "WARNING_LEVEL_1" 0 "NO_WARNING" ;
VAL_ 921 DAS_fusedSpeedLimit 31 "NONE" 0 "UNKNOWN_SNA" ;
VAL_ 921 DAS_suppressSpeedWarning 1 "Suppress_Speed_Warning" 0 "Do_Not_Suppress" ;
VAL_ 921 DAS_visionOnlySpeedLimit 31 "NONE" 0 "UNKNOWN_SNA" ;
VAL_ 921 DAS_heaterState 1 "HEATER_ON" 0 "HEATER_OFF_SNA" ;
VAL_ 921 DAS_forwardCollisionWarning 3 "SNA" 1 "FORWARD_COLLISION_WARNING" 0 "NONE" ;
VAL_ 921 DAS_autoparkReady 1 "AUTOPARK_READY" 0 "AUTOPARK_UNAVAILABLE" ;
VAL_ 921 DAS_sideCollisionAvoid 3 "SNA" 2 "AVOID_RIGHT" 1 "AVOID_LEFT" 0 "NONE" ;
VAL_ 921 DAS_sideCollisionWarning 3 "WARN_LEFT_RIGHT" 2 "WARN_RIGHT" 1 "WARN_LEFT" 0 "NONE" ;
VAL_ 921 DAS_sideCollisionInhibit 1 "INHIBIT" 0 "NO_INHIBIT" ;
VAL_ 921 DAS_csaState 3 "CSA_EXTERNAL_STATE_HOLD" 2 "CSA_EXTERNAL_STATE_ENABLE" 1 "CSA_EXTERNAL_STATE_AVAILABLE" 0 "CSA_EXTERNAL_STATE_UNAVAILABLE" ;
VAL_ 921 DAS_laneDepartureWarning 5 "SNA" 4 "RIGHT_WARNING_SEVERE" 3 "LEFT_WARNING_SEVERE" 2 "RIGHT_WARNING" 1 "LEFT_WARNING" 0 "NONE" ;
VAL_ 921 DAS_fleetSpeedState 3 "FLEETSPEED_HOLD" 2 "FLEETSPEED_ACTIVE" 1 "FLEETSPEED_AVAILABLE" 0 "FLEETSPEED_UNAVAILABLE" ;
VAL_ 921 DAS_autopilotHandsOnState 15 "LC_HANDS_ON_SNA" 8 "LC_HANDS_ON_SUSPENDED" 7 "LC_HANDS_ON_REQD_STRUCK_OUT" 5 "LC_HANDS_ON_REQD_CHIME_2" 4 "LC_HANDS_ON_REQD_CHIME_1" 3 "LC_HANDS_ON_REQD_VISUAL" 2 "LC_HANDS_ON_REQD_NOT_DETECTED" 1 "LC_HANDS_ON_REQD_DETECTED" 0 "LC_HANDS_ON_NOT_REQD" ;
VAL_ 921 DAS_autoLaneChangeState 31 "ALC_SNA" 30 "ALC_ABORT_MISSION_PLAN_INVALID" 29 "ALC_ABORT_TIMEOUT" 28 "ALC_WAITING_HANDS_ON" 27 "ALC_BLOCKED_LANE_TYPE_R" 26 "ALC_BLOCKED_LANE_TYPE_L" 25 "ALC_BLOCKED_VEH_TTC_AND_USS_R" 24 "ALC_BLOCKED_VEH_TTC_R" 23 "ALC_BLOCKED_VEH_TTC_AND_USS_L" 22 "ALC_BLOCKED_VEH_TTC_L" 21 "ALC_UNAVAILABLE_SOLID_LANE_LINE" 20 "ALC_ABORT_OTHER_REASON" 19 "ALC_ABORT_BLINKER_TURNED_OFF" 18 "ALC_ABORT_LC_HEALTH_BAD" 17 "ALC_ABORT_POOR_VIEW_RANGE" 16 "ALC_ABORT_SIDE_OBSTACLE_PRESENT_R" 15 "ALC_ABORT_SIDE_OBSTACLE_PRESENT_L" 14 "ALC_WAITING_FOR_FWD_OBST_TO_PASS_R" 13 "ALC_WAITING_FOR_FWD_OBST_TO_PASS_L" 12 "ALC_WAITING_FOR_SIDE_OBST_TO_PASS_R" 11 "ALC_WAITING_FOR_SIDE_OBST_TO_PASS_L" 10 "ALC_IN_PROGRESS_R" 9 "ALC_IN_PROGRESS_L" 8 "ALC_AVAILABLE_BOTH" 7 "ALC_AVAILABLE_ONLY_R" 6 "ALC_AVAILABLE_ONLY_L" 5 "ALC_UNAVAILABLE_VEHICLE_SPEED" 4 "ALC_UNAVAILABLE_EXITING_HIGHWAY" 3 "ALC_UNAVAILABLE_TP_FOLLOW" 2 "ALC_UNAVAILABLE_SONICS_INVALID" 1 "ALC_UNAVAILABLE_NO_LANES" 0 "ALC_UNAVAILABLE_DISABLED" ;
VAL_ 1001 DAS_headlightRequest 3 "DAS_HEADLIGHT_REQUEST_INVALID" 1 "DAS_HEADLIGHT_REQUEST_ON" 0 "DAS_HEADLIGHT_REQUEST_OFF" ;
VAL_ 1001 DAS_hazardLightRequest 3 "DAS_REQUEST_HAZARDS_SNA" 2 "DAS_REQUEST_HAZARDS_UNUSED" 1 "DAS_REQUEST_HAZARDS_ON" 0 "DAS_REQUEST_HAZARDS_OFF" ;
VAL_ 1001 DAS_wiperSpeed 15 "DAS_WIPER_SPEED_INVALID" 14 "DAS_WIPER_SPEED_14" 13 "DAS_WIPER_SPEED_13" 12 "DAS_WIPER_SPEED_12" 11 "DAS_WIPER_SPEED_11" 10 "DAS_WIPER_SPEED_10" 9 "DAS_WIPER_SPEED_9" 8 "DAS_WIPER_SPEED_8" 7 "DAS_WIPER_SPEED_7" 6 "DAS_WIPER_SPEED_6" 5 "DAS_WIPER_SPEED_5" 4 "DAS_WIPER_SPEED_4" 3 "DAS_WIPER_SPEED_3" 2 "DAS_WIPER_SPEED_2" 1 "DAS_WIPER_SPEED_1" 0 "DAS_WIPER_SPEED_OFF" ;
VAL_ 1001 DAS_turnIndicatorRequest 3 "DAS_TURN_INDICATOR_CANCEL" 2 "DAS_TURN_INDICATOR_RIGHT" 1 "DAS_TURN_INDICATOR_LEFT" 0 "DAS_TURN_INDICATOR_NONE" ;
VAL_ 1001 DAS_highLowBeamDecision 3 "DAS_HIGH_BEAM_SNA" 2 "DAS_HIGH_BEAM_ON" 1 "DAS_HIGH_BEAM_OFF" 0 "DAS_HIGH_BEAM_UNDECIDED" ;
VAL_ 1001 DAS_highLowBeamOffReason 5 "HIGH_BEAM_OFF_REASON_SNA" 4 "HIGH_BEAM_OFF_REASON_HEAD_LIGHT" 3 "HIGH_BEAM_OFF_REASON_AMBIENT_LIGHT" 2 "HIGH_BEAM_OFF_REASON_MOVING_RADAR_TARGET" 1 "HIGH_BEAM_OFF_REASON_MOVING_VISION_TARGET" 0 "HIGH_BEAM_ON" ;
VAL_ 1001 DAS_turnIndicatorRequestReason 6 "DAS_ACTIVE_COMMANDED_LANE_CHANGE" 5 "DAS_CANCEL_FORK" 4 "DAS_CANCEL_LANE_CHANGE" 3 "DAS_ACTIVE_FORK" 2 "DAS_ACTIVE_SPEED_LANE_CHANGE" 1 "DAS_ACTIVE_NAV_LANE_CHANGE" 0 "DAS_NONE" ;
VAL_ 1160 DAS_steeringAngleRequest 16384 "ZERO_ANGLE" ;
VAL_ 1160 DAS_steeringControlType 1 "ANGLE_CONTROL" 3 "DISABLED" 0 "NONE" 2 "RESERVED" ;
